VERSION "Realistic CAN Trace Generator"

NS_ :

BS_:

BU_: ADAS_DOMAIN LIDAR_FRONT

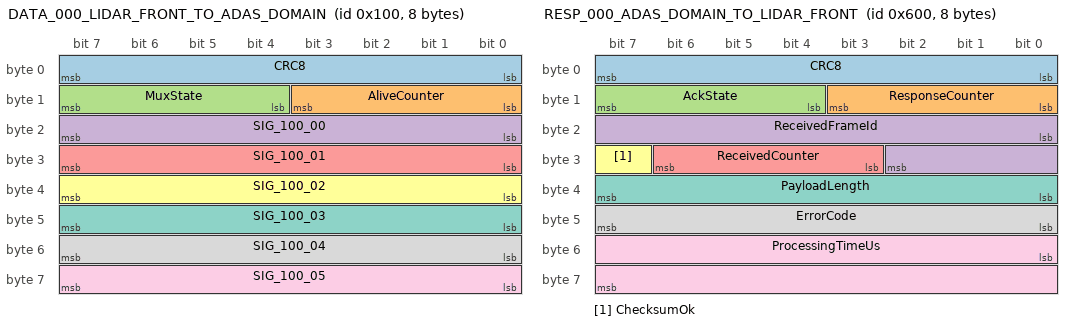
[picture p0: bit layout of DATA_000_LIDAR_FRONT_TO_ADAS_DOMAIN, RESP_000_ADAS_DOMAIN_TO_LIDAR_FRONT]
BO_ 256 DATA_000_LIDAR_FRONT_TO_ADAS_DOMAIN: 8 LIDAR_FRONT
 SG_ CRC8 : 0|8@1+ (1,0) [0|255] "" ADAS_DOMAIN
 SG_ AliveCounter : 8|4@1+ (1,0) [0|15] "" ADAS_DOMAIN
 SG_ MuxState : 12|4@1+ (1,0) [0|15] "" ADAS_DOMAIN
 SG_ SIG_100_00 : 16|8@1+ (0.1,0.0) [0|255] "rpm" ADAS_DOMAIN
 SG_ SIG_100_01 : 24|8@1+ (0.1,0.0) [0|255] "km/h" ADAS_DOMAIN
 SG_ SIG_100_02 : 32|8@1+ (0.1,0.0) [0|255] "V" ADAS_DOMAIN
 SG_ SIG_100_03 : 40|8@1+ (0.1,0.0) [0|255] "Nm" ADAS_DOMAIN
 SG_ SIG_100_04 : 48|8@1+ (0.1,0.0) [0|255] "Nm" ADAS_DOMAIN
 SG_ SIG_100_05 : 56|8@1+ (0.1,0.0) [0|255] "deg" ADAS_DOMAIN
CM_ BO_ 256 "Cycle=20ms; Channel=CAN1; Classic-CAN; NominalBitrate=125kbit/s;  Data request; receiver answers with response frame; PayloadRouteInfo='LIDAR_FRONT -> ADAS_DOMAIN' only in DBC comment because Classic CAN payload is 8 bytes; Gateway to CAN0";

BO_ 1536 RESP_000_ADAS_DOMAIN_TO_LIDAR_FRONT: 8 ADAS_DOMAIN
 SG_ CRC8 : 0|8@1+ (1,0) [0|255] "" LIDAR_FRONT
 SG_ ResponseCounter : 8|4@1+ (1,0) [0|15] "" LIDAR_FRONT
 SG_ AckState : 12|4@1+ (1,0) [0|15] "" LIDAR_FRONT
 SG_ ReceivedFrameId : 16|11@1+ (1,0) [0|2047] "" LIDAR_FRONT
 SG_ ReceivedCounter : 27|4@1+ (1,0) [0|15] "" LIDAR_FRONT
 SG_ ChecksumOk : 31|1@1+ (1,0) [0|1] "" LIDAR_FRONT
 SG_ PayloadLength : 32|8@1+ (1,0) [0|64] "byte" LIDAR_FRONT
 SG_ ErrorCode : 40|8@1+ (1,0) [0|255] "" LIDAR_FRONT
 SG_ ProcessingTimeUs : 48|16@1+ (1,0) [0|65535] "us" LIDAR_FRONT
CM_ BO_ 1536 "Cycle=20ms; Channel=CAN1; Classic-CAN; NominalBitrate=125kbit/s;  ResponseFor=0x100; ACK/NACK with CRC, DLC and counter check;";
